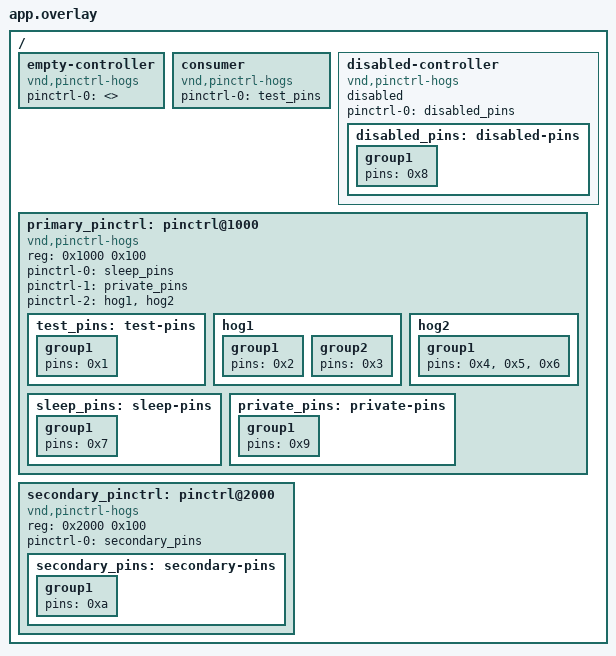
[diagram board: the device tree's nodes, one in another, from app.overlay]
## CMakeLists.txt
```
# SPDX-FileCopyrightText: Copyright (c) 2026 Axonne Inc.
# SPDX-License-Identifier: Apache-2.0

cmake_minimum_required(VERSION 3.28.0)

find_package(Zephyr REQUIRED HINTS $ENV{ZEPHYR_BASE})
project(pinctrl_hogs)

zephyr_include_directories(src)

target_sources(app PRIVATE src/main.c)
```

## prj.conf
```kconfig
# SPDX-FileCopyrightText: Copyright (c) 2026 Axonne Inc.
# SPDX-License-Identifier: Apache-2.0

CONFIG_ZTEST=y
CONFIG_PINCTRL=y
```

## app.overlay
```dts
/*
 * SPDX-FileCopyrightText: Copyright (c) 2026 Axonne Inc.
 * SPDX-License-Identifier: Apache-2.0
 */

/ {
	empty-controller {
		compatible = "vnd,pinctrl-hogs";
		pinctrl-0 = <>;
		pinctrl-names = "default";
	};

	consumer {
		compatible = "vnd,pinctrl-hogs";
		pinctrl-0 = <&test_pins>;
		pinctrl-names = "default";
	};

	disabled-controller {
		compatible = "vnd,pinctrl-hogs";
		pinctrl-0 = <&disabled_pins>;
		pinctrl-names = "default";
		status = "disabled";

		disabled_pins: disabled-pins {
			group1 {
				pins = <0x8>;
			};
		};
	};

	primary_pinctrl: pinctrl@1000 {
		compatible = "vnd,pinctrl-hogs";
		reg = <0x1000 0x100>;

		pinctrl-0 = <&sleep_pins>;
		pinctrl-1 = <&private_pins>;
		pinctrl-2 = <&hog1 &hog2>;
		pinctrl-names = "sleep", "private", "default";

		test_pins: test-pins {
			group1 {
				pins = <0x1>;
			};
		};

		hog1: hog1 {
			group1 {
				pins = <0x2>;
			};

			group2 {
				pins = <0x3>;
			};
		};

		hog2: hog2 {
			group1 {
				pins = <0x4>, <0x5>, <0x6>;
			};
		};

		sleep_pins: sleep-pins {
			group1 {
				pins = <0x7>;
			};
		};

		private_pins: private-pins {
			group1 {
				pins = <0x9>;
			};
		};
	};

	secondary_pinctrl: pinctrl@2000 {
		compatible = "vnd,pinctrl-hogs";
		reg = <0x2000 0x100>;
		pinctrl-0 = <&secondary_pins>;
		pinctrl-names = "default";

		secondary_pins: secondary-pins {
			group1 {
				pins = <0xa>;
			};
		};
	};
};
```

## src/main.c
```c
/*
 * SPDX-FileCopyrightText: Copyright (c) 2026 Axonne Inc.
 * SPDX-License-Identifier: Apache-2.0
 */

#include <zephyr/drivers/pinctrl.h>
#include <zephyr/fff.h>
#include <zephyr/ztest.h>

BUILD_ASSERT(IS_ENABLED(CONFIG_PINCTRL_HOGS),
	     "CONFIG_PINCTRL_HOGS should be enabled by devicetree");

DEFINE_FFF_GLOBALS;

FAKE_VALUE_FUNC(int, pinctrl_configure_pins, const pinctrl_soc_pin_t *, uint8_t, uintptr_t);

ZTEST(pinctrl_hogs, test_pinctrl_hog_count)
{
	const uint32_t call_count = pinctrl_configure_pins_fake.call_count;

	zassert_equal(call_count, 2, "Only the two enabled controllers should be configured");
}

ZTEST(pinctrl_hogs, test_pinctrl_hog_default_state)
{
	const pinctrl_soc_pin_t *pins = pinctrl_configure_pins_fake.arg0_history[0];
	const uint8_t pin_cnt = pinctrl_configure_pins_fake.arg1_history[0];
	const uintptr_t reg = pinctrl_configure_pins_fake.arg2_history[0];

	zassert_equal(pin_cnt, 5, "Default state should include both referenced configurations");
	zassert_not_null(pins, "Default state pins are missing");
	zassert_equal(reg, PINCTRL_REG_NONE);

	for (uint8_t i = 0; i < pin_cnt; i++) {
		zassert_equal(pins[i], i + 2, "Unexpected pin at index %u", i);
	}
}

ZTEST(pinctrl_hogs, test_pinctrl_hog_second_controller)
{
	const pinctrl_soc_pin_t *pins = pinctrl_configure_pins_fake.arg0_history[1];
	const uint8_t pin_cnt = pinctrl_configure_pins_fake.arg1_history[1];
	const uintptr_t reg = pinctrl_configure_pins_fake.arg2_history[1];

	zassert_equal(pin_cnt, 1);
	zassert_not_null(pins);
	zassert_equal(pins[0], 0xa);

	zassert_equal(reg, PINCTRL_REG_NONE);
}

ZTEST_SUITE(pinctrl_hogs, NULL, NULL, NULL, NULL, NULL);
```

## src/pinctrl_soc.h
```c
/*
 * SPDX-FileCopyrightText: Copyright (c) 2026 Axonne Inc.
 * SPDX-License-Identifier: Apache-2.0
 */

/**
 * @file
 * Testing specific helpers for pinctrl hogs.
 */

#ifndef ZEPHYR_TESTS_DRIVERS_PINCTRL_HOGS_SRC_PINCTRL_SOC_H_
#define ZEPHYR_TESTS_DRIVERS_PINCTRL_HOGS_SRC_PINCTRL_SOC_H_

#include <zephyr/devicetree.h>
#include <zephyr/types.h>

/** @cond INTERNAL_HIDDEN */

/** Test pin type. */
typedef uint32_t pinctrl_soc_pin_t;

/**
 * @brief Utility macro to initialize each pin.
 *
 * @param node_id Node identifier.
 * @param prop Property name.
 * @param idx Property entry index.
 */
#define Z_PINCTRL_STATE_PIN_INIT(node_id, prop, idx) DT_PROP_BY_IDX(node_id, prop, idx),

/**
 * @brief Utility macro to initialize pins from one state phandle.
 *
 * @param node_id Consumer node identifier.
 * @param prop Property containing state phandles.
 * @param idx Property entry index.
 */
#define Z_PINCTRL_STATE_PINS_INIT_BY_IDX(node_id, prop, idx)                                       \
	DT_FOREACH_CHILD_VARGS(DT_PHANDLE_BY_IDX(node_id, prop, idx), DT_FOREACH_PROP_ELEM, pins,  \
			       Z_PINCTRL_STATE_PIN_INIT)

/**
 * @brief Utility macro to initialize state pins referenced by a property.
 *
 * @param node_id Consumer node identifier.
 * @param prop Property containing state phandles.
 */
#define Z_PINCTRL_STATE_PINS_INIT(node_id, prop)                                                   \
	{DT_FOREACH_PROP_ELEM_SEP(node_id, prop, Z_PINCTRL_STATE_PINS_INIT_BY_IDX, ())}

/** @endcond */

#endif /* ZEPHYR_TESTS_DRIVERS_PINCTRL_HOGS_SRC_PINCTRL_SOC_H_ */
```
